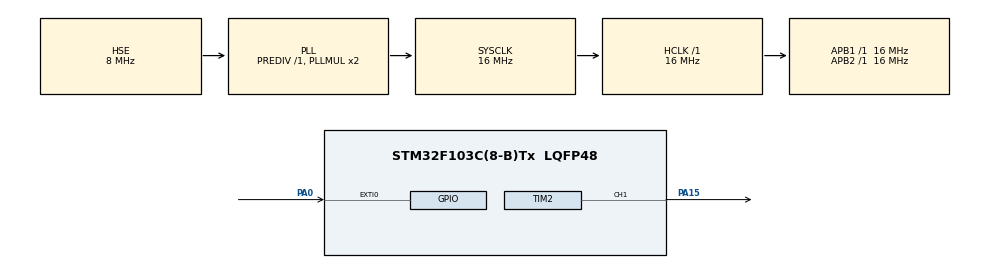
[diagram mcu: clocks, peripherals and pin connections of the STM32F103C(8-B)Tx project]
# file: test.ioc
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Mcu.Family=STM32F1
Mcu.Name=STM32F103C(8-B)Tx
Mcu.Package=LQFP48
NVIC.EXTI0_IRQn=true\:0\:0\:false\:false\:true\:true\:true
NVIC.PriorityGroup=NVIC_PRIORITYGROUP_4
NVIC.RCC_IRQn=true\:0\:0\:false\:false\:true\:true\:false
NVIC.TIM2_IRQn=true\:0\:0\:false\:false\:true\:true\:true
PA0-WKUP.GPIO_ModeDefaultEXTI=GPIO_MODE_IT_RISING_FALLING
PA0-WKUP.GPIO_PuPd=GPIO_PULLDOWN
PA0-WKUP.Signal=GPXTI0
PA13.Mode=Serial_Wire
PA13.Signal=SYS_JTMS-SWDIO
PA14.Mode=Serial_Wire
PA14.Signal=SYS_JTCK-SWCLK
PA15.Signal=S_TIM2_CH1_ETR
PD0-OSC_IN.Mode=HSE-External-Oscillator
PD0-OSC_IN.Signal=RCC_OSC_IN
PD1-OSC_OUT.Mode=HSE-External-Oscillator
PD1-OSC_OUT.Signal=RCC_OSC_OUT
ProjectManager.HeapSize=0x200
ProjectManager.StackSize=0x400
ProjectManager.TargetToolchain=MDK-ARM V5
RCC.AHBFreq_Value=16000000
RCC.APB1Freq_Value=16000000
RCC.APB1TimFreq_Value=16000000
RCC.APB2Freq_Value=16000000
RCC.APB2TimFreq_Value=16000000
RCC.HCLKFreq_Value=16000000
RCC.PLLSourceVirtual=RCC_PLLSOURCE_HSE
RCC.SYSCLKFreq_VALUE=16000000
RCC.SYSCLKSource=RCC_SYSCLKSOURCE_PLLCLK
RCC.USBFreq_Value=16000000
SH.S_TIM2_CH1_ETR.0=TIM2_CH1,PWM Generation1 CH1
TIM2.Channel-PWM\ Generation1\ CH1=TIM_CHANNEL_1
TIM2.OCPolarity_1=TIM_OCPOLARITY_LOW
TIM2.Period=999
TIM2.Prescaler=15
VP_TIM2_VS_ClockSourceINT.Mode=Internal
board=custom

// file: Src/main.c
/* USER CODE BEGIN Header */
/**
  ******************************************************************************
  * @file           : main.c
  * @brief          : Main program body
  ******************************************************************************
  * @attention
  *
  * <h2><center>&copy; Copyright (c) 2021 STMicroelectronics.
  * All rights reserved.</center></h2>
  *
  * This software component is licensed by ST under BSD 3-Clause license,
  * the "License"; You may not use this file except in compliance with the
  * License. You may obtain a copy of the License at:
  *                        opensource.org/licenses/BSD-3-Clause
  *
  ******************************************************************************
  */
/* USER CODE END Header */

#include "main.h"
#include "tim.h"
#include "gpio.h"

void SystemClock_Config(void);

/* USER CODE BEGIN 0 */
#define x 1000
uint8_t state;
uint16_t cmp;
uint32_t tick;
/* USER CODE END 0 */

int main(void)
{

  /* MCU Configuration--------------------------------------------------------*/

  /* Reset of all peripherals, Initializes the Flash interface and the Systick. */
  HAL_Init();

  /* Configure the system clock */
  SystemClock_Config();

  /* Initialize all configured peripherals */
  MX_GPIO_Init();
  MX_TIM2_Init();
  /* USER CODE BEGIN 2 */
	state=0;
	HAL_TIM_PWM_Start(&htim2,TIM_CHANNEL_1);
  /* USER CODE END 2 */

  /* Infinite loop */
  while (1)
  {

    /* USER CODE BEGIN 3 */
		HAL_Delay(100);
		switch(state)
		{
			case 0:
				cmp=0;
				break;
			case 1:
				cmp=999;
				break;
			case 2:
				cmp-=1;
				if((short int)cmp<=0)
				{
					state=0;
					cmp=0;
				}
				break;
		}
		__HAL_TIM_SET_COMPARE(&htim2,TIM_CHANNEL_1,cmp);
		//__HAL_TIM_SET_COMPARE()
  }
  /* USER CODE END 3 */
}

void SystemClock_Config(void)
{
  RCC_OscInitTypeDef RCC_OscInitStruct = {0};
  RCC_ClkInitTypeDef RCC_ClkInitStruct = {0};

  /** Initializes the CPU, AHB and APB busses clocks
  */
  RCC_OscInitStruct.OscillatorType = RCC_OSCILLATORTYPE_HSE;
  RCC_OscInitStruct.HSEState = RCC_HSE_ON;
  RCC_OscInitStruct.HSEPredivValue = RCC_HSE_PREDIV_DIV1;
  RCC_OscInitStruct.HSIState = RCC_HSI_ON;
  RCC_OscInitStruct.PLL.PLLState = RCC_PLL_ON;
  RCC_OscInitStruct.PLL.PLLSource = RCC_PLLSOURCE_HSE;
  RCC_OscInitStruct.PLL.PLLMUL = RCC_PLL_MUL2;
  if (HAL_RCC_OscConfig(&RCC_OscInitStruct) != HAL_OK)
  {
    Error_Handler();
  }
  /** Initializes the CPU, AHB and APB busses clocks
  */
  RCC_ClkInitStruct.ClockType = RCC_CLOCKTYPE_HCLK|RCC_CLOCKTYPE_SYSCLK
                              |RCC_CLOCKTYPE_PCLK1|RCC_CLOCKTYPE_PCLK2;
  RCC_ClkInitStruct.SYSCLKSource = RCC_SYSCLKSOURCE_PLLCLK;
  RCC_ClkInitStruct.AHBCLKDivider = RCC_SYSCLK_DIV1;
  RCC_ClkInitStruct.APB1CLKDivider = RCC_HCLK_DIV1;
  RCC_ClkInitStruct.APB2CLKDivider = RCC_HCLK_DIV1;

  if (HAL_RCC_ClockConfig(&RCC_ClkInitStruct, FLASH_LATENCY_0) != HAL_OK)
  {
    Error_Handler();
  }
}

/* USER CODE BEGIN 4 */
void HAL_GPIO_EXTI_Callback(uint16_t GPIO_Pin)
{
	if(HAL_GPIO_ReadPin(GPIOA,GPIO_PIN_0)==GPIO_PIN_RESET)//��ס
	{
		state=1;//����
		tick=HAL_GetTick();//��ȡ�����
	}
	else if(HAL_GetTick()-tick< x)
	{
		state=2;//����
		cmp=999;
	}
	else
		state=0;//����
	return ;
}
/* USER CODE END 4 */

void Error_Handler(void)
{
}

/************************ (C) COPYRIGHT STMicroelectronics *****END OF FILE****/
